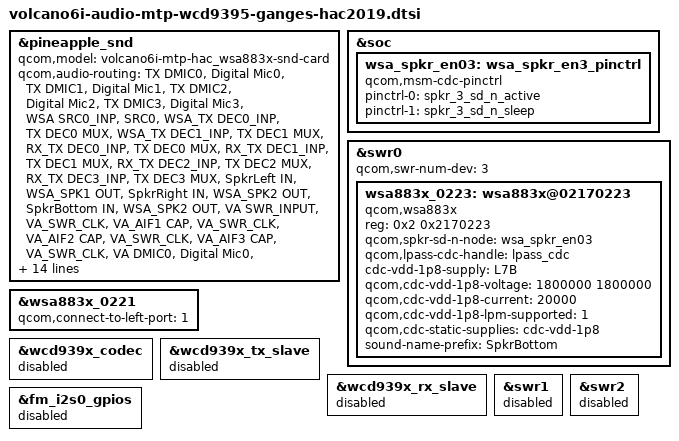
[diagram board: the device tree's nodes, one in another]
#include "volcano6i-audio-mtp-wcd9395.dtsi"
#include "volcano-audio-bt-swr.dtsi"

&pineapple_snd {
	/delete-property/ qcom,pri-mi2s-gpios;
	qcom,model = "volcano6i-mtp-hac_wsa883x-snd-card";
	qcom,audio-routing =
		"TX DMIC0", "Digital Mic0",
		"TX DMIC1", "Digital Mic1",
		"TX DMIC2", "Digital Mic2",
		"TX DMIC3", "Digital Mic3",
		"WSA SRC0_INP", "SRC0",
		"WSA_TX DEC0_INP", "TX DEC0 MUX",
		"WSA_TX DEC1_INP", "TX DEC1 MUX",
		"RX_TX DEC0_INP", "TX DEC0 MUX",
		"RX_TX DEC1_INP", "TX DEC1 MUX",
		"RX_TX DEC2_INP", "TX DEC2 MUX",
		"RX_TX DEC3_INP", "TX DEC3 MUX",
		"SpkrLeft IN", "WSA_SPK1 OUT",
		"SpkrRight IN", "WSA_SPK2 OUT",
		"SpkrBottom IN", "WSA_SPK2 OUT",
		"VA SWR_INPUT", "VA_SWR_CLK",
		"VA_AIF1 CAP", "VA_SWR_CLK",
		"VA_AIF2 CAP", "VA_SWR_CLK",
		"VA_AIF3 CAP", "VA_SWR_CLK",
		"VA DMIC0", "Digital Mic0",
		"VA DMIC1", "Digital Mic1",
		"VA DMIC2", "Digital Mic2",
		"VA DMIC3", "Digital Mic3",
		"VA DMIC0", "VA MIC BIAS",
		"VA DMIC1", "VA MIC BIAS",
		"VA DMIC2", "VA MIC BIAS",
		"VA DMIC3", "VA MIC BIAS";
	asoc-codec = <&stub_codec>, <&lpass_cdc>,
			<&wsa883x_0221>, <&wsa883x_0222>,
			<&wsa883x_0223>;
	asoc-codec-names = "msm-stub-codec.1", "lpass-cdc",
			"wsa-codec1", "wsa-codec2",
			"wsa-codec3";
	qcom,wsa-max-devs = <3>;
	qcom,wsa-hac-en = <1>;
	qcom,wcn-bt = <0>;
	qcom,wcn-btfm-proxy = <1>;
	qcom,wcd-disabled = <1>;
};

&soc {
	wsa_spkr_en03: wsa_spkr_en3_pinctrl {
		compatible = "qcom,msm-cdc-pinctrl";
		pinctrl-names = "aud_active", "aud_sleep";
		pinctrl-0 = <&spkr_3_sd_n_active>;
		pinctrl-1 = <&spkr_3_sd_n_sleep>;
	};
};

&swr0 {
	qcom,swr-num-dev = <3>;
	wsa883x_0223: wsa883x@02170223 {
		compatible = "qcom,wsa883x";
		reg = <0x2 0x2170223>;
		qcom,spkr-sd-n-node = <&wsa_spkr_en03>;
		qcom,lpass-cdc-handle = <&lpass_cdc>;
		cdc-vdd-1p8-supply = <&L7B>;
		qcom,cdc-vdd-1p8-voltage = <1800000 1800000>;
		qcom,cdc-vdd-1p8-current = <20000>;
		qcom,cdc-vdd-1p8-lpm-supported = <1>;
		qcom,cdc-static-supplies = "cdc-vdd-1p8";
		sound-name-prefix = "SpkrBottom";
	};
};

&wsa883x_0221 {
	qcom,connect-to-left-port = <1>;
};

&wcd939x_codec {
	status = "disabled";
};

&wcd939x_tx_slave {
	status = "disabled";
};

&wcd939x_rx_slave {
	status = "disabled";
};

&swr1 {
	status = "disabled";
};

&swr2 {
	status = "disabled";
};

&fm_i2s0_gpios {
	status = "disabled";
};
